AUTOSAR XML (schema 00044)
package /ComponentTypes
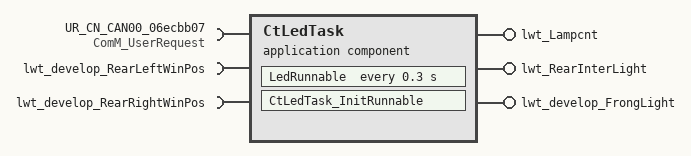
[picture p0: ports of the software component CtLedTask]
  application sw component type CtLedTask
    require port UR_CN_CAN00_06ecbb07: required-com-specs=[RequestComMode, GetCurrentComMode, GetMaxComMode, GetRequestedComMode], required-interface=ComM_UserRequest
    provide port lwt_Lampcnt: nonqueued-sender-com-spec{data-element=u8_lwt_Signal, init-value=0}, provided-interface=lwt_Lampcnt
    provide port lwt_RearInterLight: nonqueued-sender-com-spec{data-element=Bool_lwtSignal, init-value=0}, provided-interface=lwt_RearInterLight
    provide port lwt_develop_FrongLight: nonqueued-sender-com-spec{data-element=bool_signal_lwt_develop, init-value=0}, provided-interface=lwt_develop_FrongLight
    require port lwt_develop_RearLeftWinPos: nonqueued-receiver-com-spec{data-element=u8_signal_lwt_develop, init-value=0}, required-interface=lwt_develop_RearLeftWinPos
    require port lwt_develop_RearRightWinPos: nonqueued-receiver-com-spec{data-element=u8_signal_lwt_develop, init-value=0}, required-interface=lwt_develop_RearRightWinPos
    behavior CtLedTask_InternalBehavior
      timing event TMT_LedRunnable: start-on-event=LedRunnable, period=0.3
      init event CtLedTask_InitEvent: start-on-event=CtLedTask_InitRunnable
      runnable LedRunnable
        data-receive-point-by-arguments:
          access REC_lwt_develop_RearLeftWinPos_u8_signal_lwt_develop: accessed-variable=lwt_develop_RearLeftWinPos.u8_signal_lwt_develop
          access REC_lwt_develop_RearRightWinPos_u8_signal_lwt_develop: accessed-variable=lwt_develop_RearRightWinPos.u8_signal_lwt_develop
        data-send-points:
          access SEND_lwt_Lampcnt_u8_lwt_Signal: accessed-variable=lwt_Lampcnt.u8_lwt_Signal
          access SEND_lwt_RearInterLight_Bool_lwtSignal: accessed-variable=lwt_RearInterLight.Bool_lwtSignal
          access SEND_lwt_develop_FrongLight_bool_signal_lwt_develop: accessed-variable=lwt_develop_FrongLight.bool_signal_lwt_develop
      runnable CtLedTask_InitRunnable
        4 x sync call:
          SC_UR_CN_CAN00_06ecbb07_GetCurrentComMode: operation=UR_CN_CAN00_06ecbb07.GetCurrentComMode
          SC_UR_CN_CAN00_06ecbb07_GetMaxComMode: operation=UR_CN_CAN00_06ecbb07.GetMaxComMode
          SC_UR_CN_CAN00_06ecbb07_GetRequestedComMode: operation=UR_CN_CAN00_06ecbb07.GetRequestedComMode
          SC_UR_CN_CAN00_06ecbb07_RequestComMode: operation=UR_CN_CAN00_06ecbb07.RequestComMode
  swc implementation CtLedTask_Implementation: behavior=CtLedTask_InternalBehavior
